AUTOSAR XML (schema 4-3-1)
package /TPC_Composition/Components
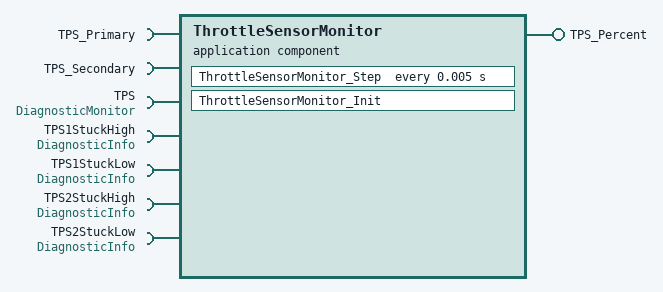
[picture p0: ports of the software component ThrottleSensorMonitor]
  application sw component type ThrottleSensorMonitor
    require port TPS_Primary: nonqueued-receiver-com-spec{data-element=Value, init-value=0}, required-interface=TPS_Primary
    require port TPS_Secondary: nonqueued-receiver-com-spec{data-element=Value, init-value=0}, required-interface=TPS_Secondary
    provide port TPS_Percent: nonqueued-sender-com-spec{data-element=Value, init-value=0}, provided-interface=TPS_Percent
    5 x require port:
      TPS: required-interface=DiagnosticMonitor
      TPS1StuckHigh: required-interface=DiagnosticInfo
      TPS1StuckLow: required-interface=DiagnosticInfo
      TPS2StuckHigh: required-interface=DiagnosticInfo
      TPS2StuckLow: required-interface=DiagnosticInfo
    behavior ThrottleSensorMonitor_IB: handle-termination-and-restart=NO-SUPPORT
      timing event Event_ThrottleSensorMonitor_Step: start-on-event=ThrottleSensorMonitor_Step, period=0.005
      runnable ThrottleSensorMonitor_Init
      runnable ThrottleSensorMonitor_Step
        data-read-access:
          access IN_TPS_Secondary_Value: accessed-variable=TPS_Secondary.Value
          access IN_TPS_Primary_Value: accessed-variable=TPS_Primary.Value
        data-write-access:
          access OUT_TPS_Percent_Value: accessed-variable=TPS_Percent.Value
        5 x sync call, all with timeout=1.0E-06:
          SC_TPS1StuckHigh_GetEventFailed: operation=TPS1StuckHigh.GetEventFailed
          SC_TPS1StuckLow_GetEventFailed: operation=TPS1StuckLow.GetEventFailed
          SC_TPS2StuckHigh_GetEventFailed: operation=TPS2StuckHigh.GetEventFailed
          SC_TPS2StuckLow_GetEventFailed: operation=TPS2StuckLow.GetEventFailed
          SC_TPS_SetEventStatus: operation=TPS.SetEventStatus
